# LM3S2616 register map
File version: 7944
Registers are 32-bit, read-write, no defined reset value unless marked. A register's access mark holds for its fields unless they carry their own. Offsets are from the block's base; [hi:lo] are bit positions.

## TIMER0 — Register map for TIMER0 peripheral
Base 0x40030000; register names take the prefix TIMER0
Same registers: TIMER1 0x40031000 (register names take the prefix TIMER1), TIMER2 0x40032000 (register names take the prefix TIMER2), TIMER3 0x40033000 (register names take the prefix TIMER3)
0x00 CFG — GPTM Configuration
  [2:0] TIMER_CFG
    0=TIMER_CFG_32_BIT_TIMER (32-bit timer configuration); 4=TIMER_CFG_16_BIT (16-bit timer configuration. The function is controlled by bits 1:0 of GPTMTAMR and GPTMTBMR)
0x04 TAMR — GPTM Timer A Mode
  [1:0] TIMER_TAMR_TAMR
    1=TIMER_TAMR_TAMR_1_SHOT (One-Shot Timer mode); 2=TIMER_TAMR_TAMR_PERIOD (Periodic Timer mode)
0x08 TBMR — GPTM Timer B Mode
  [1:0] TIMER_TBMR_TBMR
    1=TIMER_TBMR_TBMR_1_SHOT (One-Shot Timer mode); 2=TIMER_TBMR_TBMR_PERIOD (Periodic Timer mode)
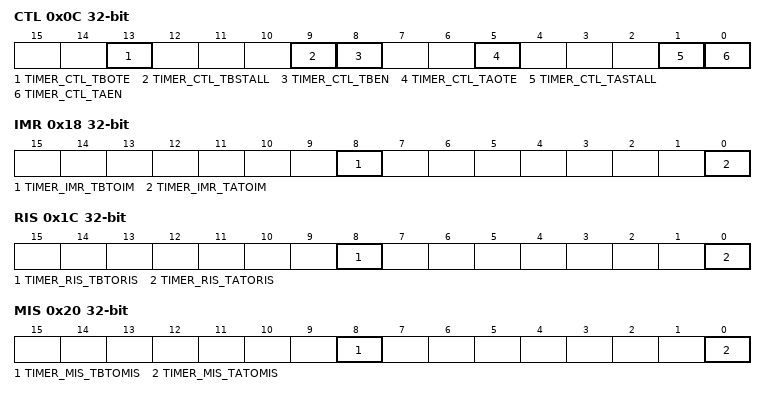
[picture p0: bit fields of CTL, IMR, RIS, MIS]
0x0C CTL — GPTM Control
  [13] TIMER_CTL_TBOTE — GPTM Timer B Output Trigger Enable
  [9] TIMER_CTL_TBSTALL — GPTM Timer B Stall Enable
  [8] TIMER_CTL_TBEN — GPTM Timer B Enable
  [5] TIMER_CTL_TAOTE — GPTM Timer A Output Trigger Enable
  [1] TIMER_CTL_TASTALL — GPTM Timer A Stall Enable
  [0] TIMER_CTL_TAEN — GPTM Timer A Enable
0x18 IMR — GPTM Interrupt Mask
  [8] TIMER_IMR_TBTOIM — GPTM Timer B Time-Out Interrupt Mask
  [0] TIMER_IMR_TATOIM — GPTM Timer A Time-Out Interrupt Mask
0x1C RIS — GPTM Raw Interrupt Status
  [8] TIMER_RIS_TBTORIS — GPTM Timer B Time-Out Raw Interrupt
  [0] TIMER_RIS_TATORIS — GPTM Timer A Time-Out Raw Interrupt
0x20 MIS — GPTM Masked Interrupt Status
  [8] TIMER_MIS_TBTOMIS — GPTM Timer B Time-Out Masked Interrupt
  [0] TIMER_MIS_TATOMIS — GPTM Timer A Time-Out Masked Interrupt
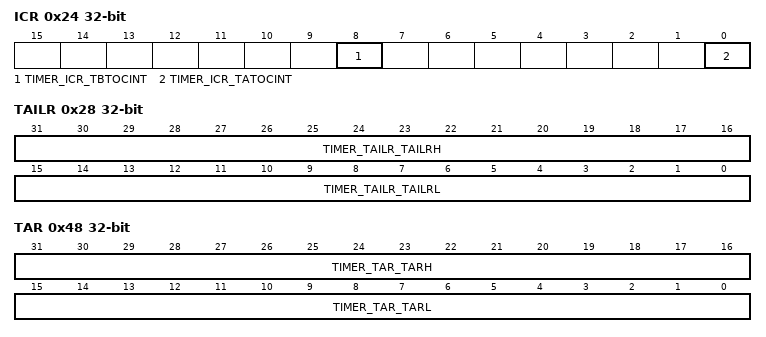
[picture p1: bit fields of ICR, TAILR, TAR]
0x24 ICR wo — GPTM Interrupt Clear
  [8] TIMER_ICR_TBTOCINT — GPTM Timer B Time-Out Interrupt Clear
  [0] TIMER_ICR_TATOCINT — GPTM Timer A Time-Out Raw Interrupt
0x28 TAILR — GPTM Timer A Interval Load
  [31:16] TIMER_TAILR_TAILRH — GPTM Timer A Interval Load Register High
  [15:0] TIMER_TAILR_TAILRL — GPTM Timer A Interval Load Register Low
0x2C TBILR — GPTM Timer B Interval Load
  [15:0] TIMER_TBILR_TBILRL — GPTM Timer B Interval Load Register
0x38 TAPR — GPTM Timer A Prescale
  [7:0] TIMER_TAPR_TAPSR
0x3C TBPR — GPTM Timer B Prescale
  [7:0] TIMER_TBPR_TBPSR
0x48 TAR — GPTM Timer A
  [31:16] TIMER_TAR_TARH — GPTM Timer A Register High
  [15:0] TIMER_TAR_TARL — GPTM Timer A Register Low
0x4C TBR — GPTM Timer B
  [15:0] TIMER_TBR_TBRL

## COMP — Register map for COMP peripheral
Base 0x4003C000; register names take the prefix COMP
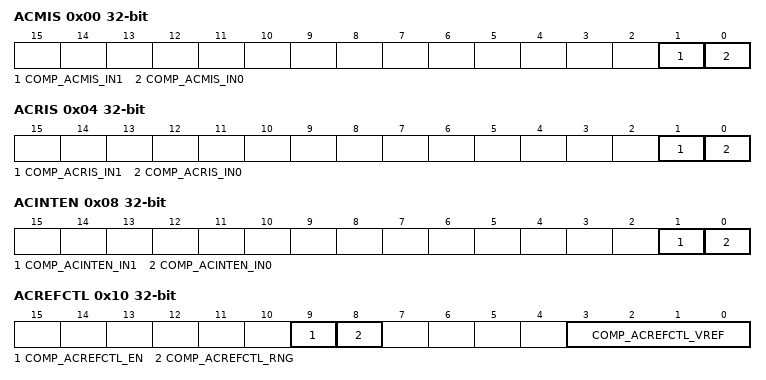
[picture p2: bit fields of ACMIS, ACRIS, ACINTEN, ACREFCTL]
0x00 ACMIS — Analog Comparator Masked Interrupt Status
  [1] COMP_ACMIS_IN1 — Comparator 1 Masked Interrupt Status
  [0] COMP_ACMIS_IN0 — Comparator 0 Masked Interrupt Status
0x04 ACRIS — Analog Comparator Raw Interrupt Status
  [1] COMP_ACRIS_IN1 — Comparator 1 Interrupt Status
  [0] COMP_ACRIS_IN0 — Comparator 0 Interrupt Status
0x08 ACINTEN — Analog Comparator Interrupt Enable
  [1] COMP_ACINTEN_IN1 — Comparator 1 Interrupt Enable
  [0] COMP_ACINTEN_IN0 — Comparator 0 Interrupt Enable
0x10 ACREFCTL — Analog Comparator Reference Voltage Control
  [9] COMP_ACREFCTL_EN — Resistor Ladder Enable
  [8] COMP_ACREFCTL_RNG — Resistor Ladder Range
  [3:0] COMP_ACREFCTL_VREF — Resistor Ladder Voltage Ref
0x20 ACSTAT0 — Analog Comparator Status 0
  [1] COMP_ACSTAT0_OVAL — Comparator Output Value
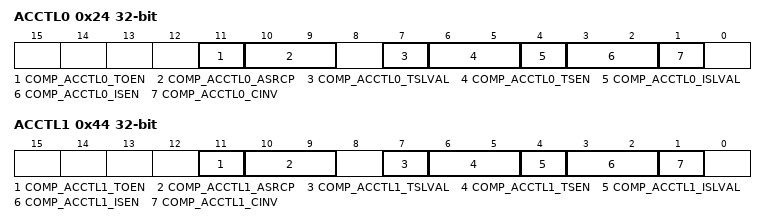
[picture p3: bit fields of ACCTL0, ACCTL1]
0x24 ACCTL0 — Analog Comparator Control 0
  [11] COMP_ACCTL0_TOEN — Trigger Output Enable
  [10:9] COMP_ACCTL0_ASRCP — Analog Source Positive
    0=COMP_ACCTL0_ASRCP_PIN (Pin value of Cn+); 1=COMP_ACCTL0_ASRCP_PIN0 (Pin value of C0+); 2=COMP_ACCTL0_ASRCP_REF (Internal voltage reference (VIREF))
  [7] COMP_ACCTL0_TSLVAL — Trigger Sense Level Value
  [6:5] COMP_ACCTL0_TSEN — Trigger Sense
    0=COMP_ACCTL0_TSEN_LEVEL (Level sense, see TSLVAL); 1=COMP_ACCTL0_TSEN_FALL (Falling edge); 2=COMP_ACCTL0_TSEN_RISE (Rising edge); 3=COMP_ACCTL0_TSEN_BOTH (Either edge)
  [4] COMP_ACCTL0_ISLVAL — Interrupt Sense Level Value
  [3:2] COMP_ACCTL0_ISEN — Interrupt Sense
    0=COMP_ACCTL0_ISEN_LEVEL (Level sense, see ISLVAL); 1=COMP_ACCTL0_ISEN_FALL (Falling edge); 2=COMP_ACCTL0_ISEN_RISE (Rising edge); 3=COMP_ACCTL0_ISEN_BOTH (Either edge)
  [1] COMP_ACCTL0_CINV — Comparator Output Invert
0x40 ACSTAT1 — Analog Comparator Status 1
  [1] COMP_ACSTAT1_OVAL — Comparator Output Value
0x44 ACCTL1 — Analog Comparator Control 1
  [11] COMP_ACCTL1_TOEN — Trigger Output Enable
  [10:9] COMP_ACCTL1_ASRCP — Analog Source Positive
    0=COMP_ACCTL1_ASRCP_PIN (Pin value of Cn+); 1=COMP_ACCTL1_ASRCP_PIN0 (Pin value of C0+); 2=COMP_ACCTL1_ASRCP_REF (Internal voltage reference (VIREF))
  [7] COMP_ACCTL1_TSLVAL — Trigger Sense Level Value
  [6:5] COMP_ACCTL1_TSEN — Trigger Sense
    0=COMP_ACCTL1_TSEN_LEVEL (Level sense, see TSLVAL); 1=COMP_ACCTL1_TSEN_FALL (Falling edge); 2=COMP_ACCTL1_TSEN_RISE (Rising edge); 3=COMP_ACCTL1_TSEN_BOTH (Either edge)
  [4] COMP_ACCTL1_ISLVAL — Interrupt Sense Level Value
  [3:2] COMP_ACCTL1_ISEN — Interrupt Sense
    0=COMP_ACCTL1_ISEN_LEVEL (Level sense, see ISLVAL); 1=COMP_ACCTL1_ISEN_FALL (Falling edge); 2=COMP_ACCTL1_ISEN_RISE (Rising edge); 3=COMP_ACCTL1_ISEN_BOTH (Either edge)
  [1] COMP_ACCTL1_CINV — Comparator Output Invert
